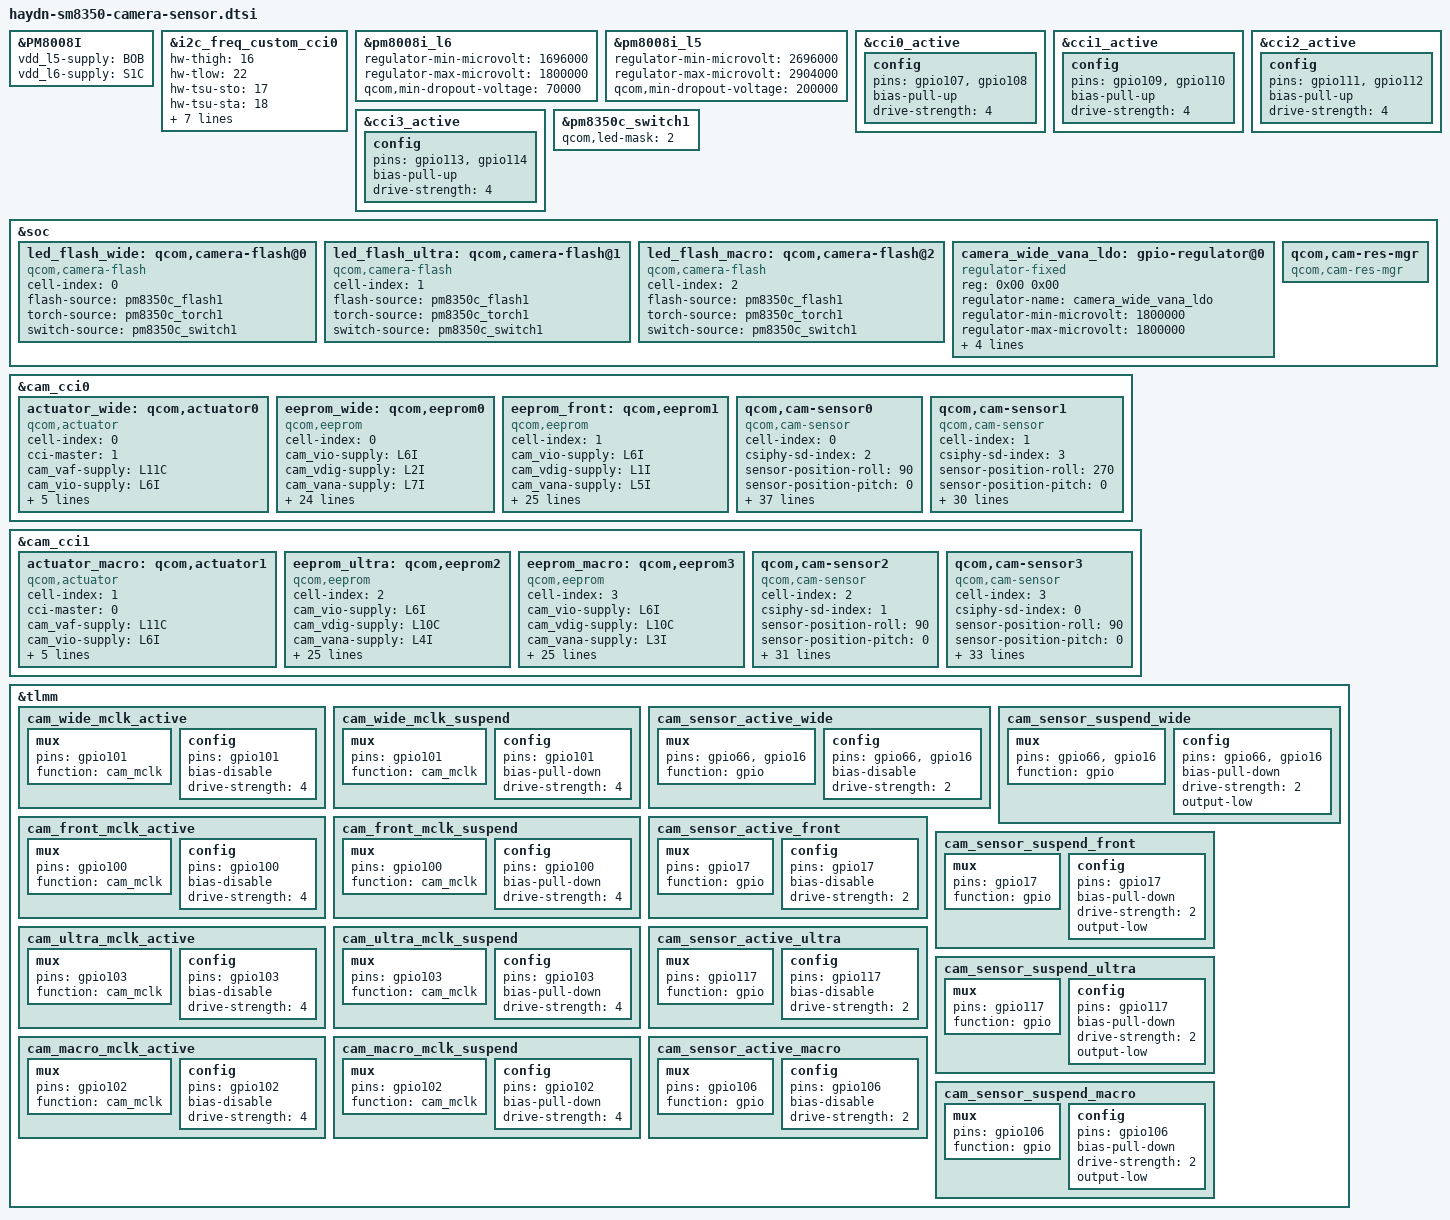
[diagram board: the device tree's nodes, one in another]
#include <dt-bindings/clock/qcom,camcc-lahaina.h>

&PM8008I {
        vdd_l5-supply = <&BOB>;
        vdd_l6-supply = <&S1C>;
};

&i2c_freq_custom_cci0 {
	hw-thigh = <16>;
	hw-tlow = <22>;
	hw-tsu-sto = <17>;
	hw-tsu-sta = <18>;
	hw-thd-dat = <16>;
	hw-thd-sta = <15>;
	hw-tbuf = <24>;
	hw-scl-stretch-en = <1>;
	hw-trdhld = <3>;
	hw-tsp = <3>;
	cci-clk-src = <37500000>;
	status = "ok";
};

&pm8008i_l6 {
        regulator-min-microvolt = <1696000>;
        regulator-max-microvolt = <1800000>;
        qcom,min-dropout-voltage = <70000>;
};

&pm8008i_l5 {
        regulator-min-microvolt = <2696000>;
        regulator-max-microvolt = <2904000>;
        qcom,min-dropout-voltage = <200000>;
};

&cci0_active {
	config {
		pins = "gpio107","gpio108";
		bias-pull-up; /* PULL UP*/
		drive-strength = <4>; /* 4 MA */
	};
};

&cci1_active {
	config {
		pins = "gpio109","gpio110";
		bias-pull-up; /* PULL UP*/
		drive-strength = <4>; /* 4 MA */
	};
};

&cci2_active {
	config {
		pins = "gpio111","gpio112";
		bias-pull-up; /* PULL UP*/
		drive-strength = <4>; /* 4 MA */
	};
};

&cci3_active {
	config {
		pins = "gpio113","gpio114";
		bias-pull-up; /* PULL UP*/
		drive-strength = <4>; /* 4 MA */
	};
};

&pm8350c_switch1 {
	qcom,led-mask = <2>; /* Channels 2*/
};

&soc {
	led_flash_wide: qcom,camera-flash@0 {
		cell-index = <0>;
		compatible = "qcom,camera-flash";
		flash-source = <&pm8350c_flash1>;
		torch-source = <&pm8350c_torch1>;
		switch-source = <&pm8350c_switch1>;
		status = "ok";
	};

	led_flash_ultra: qcom,camera-flash@1 {
		cell-index = <1>;
		compatible = "qcom,camera-flash";
		flash-source = <&pm8350c_flash1>;
		torch-source = <&pm8350c_torch1>;
		switch-source = <&pm8350c_switch1>;
		status = "ok";
	};

	led_flash_macro: qcom,camera-flash@2 {
		cell-index = <2>;
		compatible = "qcom,camera-flash";
		flash-source = <&pm8350c_flash1>;
		torch-source = <&pm8350c_torch1>;
		switch-source = <&pm8350c_switch1>;
		status = "ok";
	};

	camera_wide_vana_ldo: gpio-regulator@0 {
		compatible = "regulator-fixed";
		reg = <0x00 0x00>;
		regulator-name = "camera_wide_vana_ldo";
		regulator-min-microvolt = <1800000>;
		regulator-max-microvolt = <1800000>;
		regulator-enable-ramp-delay = <135>;
		enable-active-high;
		gpio = <&tlmm 66 0>;
                vin-supply = <&S1C>;
	};

	qcom,cam-res-mgr {
		compatible = "qcom,cam-res-mgr";
	};
};

&cam_cci0 {
        actuator_wide: qcom,actuator0 {
                cell-index = <0>;
                compatible = "qcom,actuator";
                cci-master = <1>;
                cam_vaf-supply = <&L11C>;
                cam_vio-supply = <&L6I>;
                regulator-names = "cam_vaf", "cam_vio";
                rgltr-cntrl-support;
                rgltr-min-voltage = <2800000 1800000>;
                rgltr-max-voltage = <2800000 1800000>;
                rgltr-load-current = <300000 10000>;
                status = "ok";
        };

	eeprom_wide: qcom,eeprom0 {
		cell-index = <0>;
		compatible = "qcom,eeprom";
		cam_vio-supply = <&L6I>;
		cam_vdig-supply = <&L2I>;
		cam_vana-supply = <&L7I>;
		cam_v_custom1-supply = <&camera_wide_vana_ldo>;
		cam_clk-supply = <&cam_cc_titan_top_gdsc>;
		cam_bob-supply = <&pm8350c_bob>;
		regulator-names = "cam_vio", "cam_vdig", "cam_vana", "cam_v_custom1",
			"cam_clk", "cam_bob";
		rgltr-cntrl-support;
		rgltr-min-voltage = <1800000 1104000 2904000 1800000 0 3200000>;
		rgltr-max-voltage = <1800000 1104000 2904000 1800000 0 3960000>;
		rgltr-load-current = <4800 120000 970000 87000 0 2000000>;
		gpio-no-mux = <0>;
		pinctrl-names = "cam_default", "cam_suspend";
		pinctrl-0 = <&cam_sensor_active_wide>;
		pinctrl-1 = <&cam_sensor_suspend_wide>;
		gpios = <&tlmm 101 0>,
			<&tlmm 16 0>;
		gpio-reset = <1>;
		gpio-req-tbl-num = <0 1>;
		gpio-req-tbl-flags = <1 0>;
		gpio-req-tbl-label = "CAMIF_MCLK1",
					"CAM_RESET1";
		cci-master = <1>;
		clocks = <&clock_camcc CAM_CC_MCLK1_CLK>;
		clock-names = "cam_clk";
		clock-cntl-level = "nominal";
		clock-rates = <19200000>;
		status = "ok";
	};

	eeprom_front: qcom,eeprom1 {
		cell-index = <1>;
		compatible = "qcom,eeprom";
		cam_vio-supply = <&L6I>;
		cam_vdig-supply = <&L1I>;
		cam_vana-supply = <&L5I>;
		cam_clk-supply = <&cam_cc_titan_top_gdsc>;
		cam_bob-supply = <&pm8350c_bob>;
		regulator-names = "cam_vio", "cam_vdig", "cam_vana",
			"cam_clk", "cam_bob";
		rgltr-cntrl-support;
		rgltr-min-voltage = <1800000 1056000 2800000 0 3200000>;
		rgltr-max-voltage = <1800000 1056000 2800000 0 3960000>;
		rgltr-load-current = <10000 140000 280000 0 2000000>;
		gpio-no-mux = <0>;
		pinctrl-names = "cam_default", "cam_suspend";
		pinctrl-0 = <&cam_sensor_active_front
			&cam_front_mclk_active>;
		pinctrl-1 = <&cam_sensor_suspend_front
			&cam_front_mclk_suspend>;
		gpios = <&tlmm 100 0>,
			<&tlmm 17 0>;
		gpio-reset = <1>;
		gpio-req-tbl-num = <0 1>;
		gpio-req-tbl-flags = <1 0>;
		gpio-req-tbl-label = "CAMIF_MCLK0",
					"CAM_RESET0";
		cci-master = <0>;
		clocks = <&clock_camcc CAM_CC_MCLK0_CLK>;
		clock-names = "cam_clk";
		clock-cntl-level = "nominal";
		clock-rates = <19200000>;
		status = "ok";
	};

	// wide IMX686 64M AVDD 2.8V
	// wide S5KHM2 108M AVDD 2.9V
	qcom,cam-sensor0 {
		cell-index = <0>;
		compatible = "qcom,cam-sensor";
		csiphy-sd-index = <2>;
		sensor-position-roll = <90>;
		sensor-position-pitch = <0>;
		sensor-position-yaw = <180>;
		eeprom-src = <&eeprom_wide>;
		actuator-src = <&actuator_wide>;
		led-flash-src = <&led_flash_wide>;
		cam_vio-supply = <&L6I>;
		cam_vaf_supply = <&L11C>;
		cam_vdig-supply = <&L2I>;
		cam_vana-supply = <&L7I>;
                cam_vana1-supply = <&L2I>;
		cam_v_custom1-supply = <&camera_wide_vana_ldo>;
		cam_v_custom2-supply = <&L7I>;//Hm2 AVDD
		cam_clk-supply = <&cam_cc_titan_top_gdsc>;
		cam_bob-supply = <&pm8350c_bob>;
		regulator-names = "cam_vio", "cam_vdig", "cam_vana", "cam_vaf", "cam_vana1", "cam_v_custom1", "cam_v_custom2",
			"cam_clk", "cam_bob";
		rgltr-cntrl-support;
		rgltr-min-voltage = <1800000 1104000 2904000 2800000 1056000 1800000 2800000 0 3200000>;
		rgltr-max-voltage = <1800000 1104000 2904000 2800000 1056000 1800000 2800000 0 3960000>;
		rgltr-load-current = <4800 120000 970000 106000 87000 2000000 2000000 0 2000000>;
		gpio-no-mux = <0>;
                pinctrl-names = "cam_default", "cam_suspend";
                pinctrl-0 = <&cam_sensor_active_wide
                        &cam_wide_mclk_active>;
                pinctrl-1 = <&cam_sensor_suspend_wide
                        &cam_wide_mclk_suspend>;
		gpios = <&tlmm 101 0>,
			<&tlmm 16 0>;
		gpio-reset = <1>;
		gpio-req-tbl-num = <0 1>;
		gpio-req-tbl-flags = <1 0>;
		gpio-req-tbl-label = "CAMIF_MCLK1",
					"CAM_RESET1";
		cci-master = <1>;
		clocks = <&clock_camcc CAM_CC_MCLK1_CLK>;
		clock-names = "cam_clk";
		clock-cntl-level = "nominal";
		clock-rates = <19200000>;
		status = "ok";
	};

	// Front 20M
	qcom,cam-sensor1 {
		cell-index = <1>;
		compatible = "qcom,cam-sensor";
		csiphy-sd-index = <3>;
		sensor-position-roll = <270>;
		sensor-position-pitch = <0>;
		sensor-position-yaw = <0>;
		eeprom-src = <&eeprom_front>;
		cam_vio-supply = <&L6I>;
		cam_vdig-supply = <&L1I>;
		cam_vana-supply = <&L5I>;
		cam_clk-supply = <&cam_cc_titan_top_gdsc>;
		cam_bob-supply = <&pm8350c_bob>;
		regulator-names = "cam_vio", "cam_vdig", "cam_vana",
			"cam_clk", "cam_bob";
		rgltr-cntrl-support;
		rgltr-min-voltage = <1800000 1056000 2800000 0 3200000>;
		rgltr-max-voltage = <1800000 1056000 2800000 0 3960000>;
		rgltr-load-current = <10000 140000 280000 0 2000000>;
		gpio-no-mux = <0>;
		pinctrl-names = "cam_default", "cam_suspend";
		pinctrl-0 = <&cam_sensor_active_front
			&cam_front_mclk_active>;
		pinctrl-1 = <&cam_sensor_suspend_front
			&cam_front_mclk_suspend>;
		gpios = <&tlmm 100 0>,
			<&tlmm 17 0>;
		gpio-reset = <1>;
		gpio-req-tbl-num = <0 1>;
		gpio-req-tbl-flags = <1 0>;
		gpio-req-tbl-label = "CAMIF_MCLK0",
					"CAM_RESET0";
		cci-master = <0>;
		clocks = <&clock_camcc CAM_CC_MCLK0_CLK>;
		clock-names = "cam_clk";
		clock-cntl-level = "nominal";
		clock-rates = <19200000>;
		status = "ok";
	};

};

&cam_cci1 {
        actuator_macro: qcom,actuator1 {
                cell-index = <1>;
                compatible = "qcom,actuator";
                cci-master = <0>;
                cam_vaf-supply = <&L11C>;
                cam_vio-supply = <&L6I>;
                regulator-names = "cam_vaf", "cam_vio";
                rgltr-cntrl-support;
                rgltr-min-voltage = <2800000 1800000>;
                rgltr-max-voltage = <2800000 1800000>;
                rgltr-load-current = <300000 10000>;
                status = "ok";
        };

	eeprom_ultra: qcom,eeprom2 {
		cell-index = <2>;
		compatible = "qcom,eeprom";
		cam_vio-supply = <&L6I>;
		cam_vdig-supply = <&L10C>;
		cam_vana-supply = <&L4I>;
		cam_clk-supply = <&cam_cc_titan_top_gdsc>;
		cam_bob-supply = <&pm8350c_bob>;
		regulator-names = "cam_vio", "cam_vdig", "cam_vana"
			,"cam_clk", "cam_bob";
		rgltr-cntrl-support;
		rgltr-min-voltage = <1800000 1200000 2704000 0 3200000>;
		rgltr-max-voltage = <1800000 1200000 2704000 0 3960000>;
		rgltr-load-current = <10000 140000 180000 0 2000000>;
		gpio-no-mux = <0>;
		pinctrl-names = "cam_default", "cam_suspend";
		pinctrl-0 = <&cam_sensor_active_ultra
				&cam_ultra_mclk_active>;
		pinctrl-1 = <&cam_sensor_suspend_ultra
				&cam_ultra_mclk_suspend>;
		gpios = <&tlmm 103 0>,
			<&tlmm 117 0>;
		gpio-reset = <1>;
		gpio-req-tbl-num = <0 1>;
		gpio-req-tbl-flags = <1 0>;
		gpio-req-tbl-label = "CAMIF_MCLK3",
					"CAM_RESET3";
		cci-master = <1>;
		clocks = <&clock_camcc CAM_CC_MCLK3_CLK>;
		clock-names = "cam_clk";
		clock-cntl-level = "nominal";
		clock-rates = <19200000>;
		status = "ok";
	};

	eeprom_macro: qcom,eeprom3 {
		cell-index = <3>;
		compatible = "qcom,eeprom";
		cam_vio-supply = <&L6I>;
		cam_vdig-supply = <&L10C>;
		cam_vana-supply = <&L3I>;
		cam_clk-supply = <&cam_cc_titan_top_gdsc>;
		cam_bob-supply = <&pm8350c_bob>;
		regulator-names = "cam_vio", "cam_vdig", "cam_vana"
			          , "cam_clk", "cam_bob";
		rgltr-cntrl-support;
		rgltr-min-voltage = <1800000 1200000 2800000 0 3200000>;
		rgltr-max-voltage = <1800000 1200000 2800000 0 3960000>;
		rgltr-load-current = <10000 140000 180000 0 2000000>;
		gpio-no-mux = <0>;
		pinctrl-names = "cam_default", "cam_suspend";
		pinctrl-0 = <&cam_sensor_active_macro
				&cam_macro_mclk_active>;
		pinctrl-1 = <&cam_sensor_suspend_macro
				&cam_macro_mclk_suspend>;
		gpios = <&tlmm 102 0>,
			<&tlmm 106 0>;
		gpio-reset = <1>;
		gpio-req-tbl-num = <0 1>;
		gpio-req-tbl-flags = <1 0>;
		gpio-req-tbl-label = "CAMIF_MCLK2",
					"CAM_RESET2";
		cci-master = <0>;
		clocks = <&clock_camcc CAM_CC_MCLK2_CLK>;
		clock-names = "cam_clk";
		clock-cntl-level = "nominal";
		clock-rates = <19200000>;
		status = "ok";
	};

	// Ultra 8M
	qcom,cam-sensor2 {
		cell-index = <2>;
		compatible = "qcom,cam-sensor";
		csiphy-sd-index = <1>;
		sensor-position-roll = <90>;
		sensor-position-pitch = <0>;
		sensor-position-yaw = <180>;
		eeprom-src = <&eeprom_ultra>;
		//actuator-src = <&actuator_ultra>;
		led-flash-src = <&led_flash_ultra>;
		cam_vio-supply = <&L6I>;
		cam_vdig-supply = <&L10C>;
		cam_vana-supply = <&L4I>;
		cam_clk-supply = <&cam_cc_titan_top_gdsc>;
		cam_bob-supply = <&pm8350c_bob>;
		regulator-names = "cam_vio", "cam_vdig", "cam_vana"
			,"cam_clk", "cam_bob";
		rgltr-cntrl-support;
		rgltr-min-voltage = <1800000 1200000 2704000 0 3200000>;
		rgltr-max-voltage = <1800000 1200000 2704000 0 3960000>;
		rgltr-load-current = <10000 140000 180000 0 2000000>;
		gpio-no-mux = <0>;
		pinctrl-names = "cam_default", "cam_suspend";
		pinctrl-0 = <&cam_sensor_active_ultra
				&cam_ultra_mclk_active>;
		pinctrl-1 = <&cam_sensor_suspend_ultra
				&cam_ultra_mclk_suspend>;
		gpios = <&tlmm 103 0>,
			<&tlmm 117 0>;
		gpio-reset = <1>;
		gpio-req-tbl-num = <0 1>;
		gpio-req-tbl-flags = <1 0>;
		gpio-req-tbl-label = "CAMIF_MCLK3",
					"CAM_RESET3";
		cci-master = <1>;
		clocks = <&clock_camcc CAM_CC_MCLK3_CLK>;
		clock-names = "cam_clk";
		clock-cntl-level = "nominal";
		clock-rates = <19200000>;
		status = "ok";
	};

	// Folded 5M MACRO
	qcom,cam-sensor3 {
		cell-index = <3>;
		compatible = "qcom,cam-sensor";
		csiphy-sd-index = <0>;
		sensor-position-roll = <90>;
		sensor-position-pitch = <0>;
		sensor-position-yaw = <180>;
		eeprom-src = <&eeprom_macro>;
		led-flash-src = <&led_flash_macro>;
		actuator-src = <&actuator_macro>;
		cam_vio-supply = <&L6I>;
		cam_vdig-supply = <&L10C>;
		cam_vana-supply = <&L3I>;
		cam_vaf-supply = <&L11C>;
		cam_clk-supply = <&cam_cc_titan_top_gdsc>;
		cam_bob-supply = <&pm8350c_bob>;
		regulator-names = "cam_vio", "cam_vdig", "cam_vana", "cam_vaf"
			          , "cam_clk", "cam_bob";
		rgltr-cntrl-support;
		rgltr-min-voltage = <1800000 1200000 2800000 2800000 0 3200000>;
		rgltr-max-voltage = <1800000 1200000 2800000 2800000 0 3960000>;
		rgltr-load-current = <10000 140000 180000 296000 0 2000000>;
		gpio-no-mux = <0>;
		pinctrl-names = "cam_default", "cam_suspend";
		pinctrl-0 = <&cam_sensor_active_macro
				&cam_macro_mclk_active>;
		pinctrl-1 = <&cam_sensor_suspend_macro
				&cam_macro_mclk_suspend>;
		gpios = <&tlmm 102 0>,
			<&tlmm 106 0>;
		gpio-reset = <1>;
		gpio-req-tbl-num = <0 1>;
		gpio-req-tbl-flags = <1 0>;
		gpio-req-tbl-label = "CAMIF_MCLK2",
					"CAM_RESET2";
		cci-master = <0>;
		clocks = <&clock_camcc CAM_CC_MCLK2_CLK>;
		clock-names = "cam_clk";
		clock-cntl-level = "nominal";
		clock-rates = <19200000>;
		status = "ok";
	};
};

&tlmm {
	cam_wide_mclk_active: cam_wide_mclk_active {
                mux {
                        pins = "gpio101";
                        function = "cam_mclk";
                    };

                config {
                        pins = "gpio101";
                        bias-disable; /* No PULL */
                        drive-strength = <4>; /* 4 MA */
                };
	};

	cam_wide_mclk_suspend: cam_wide_mclk_suspend {
                mux {
                        pins = "gpio101";
                        function = "cam_mclk";
                };

                config {
                        pins = "gpio101";
                        bias-pull-down; /* PULL DOWN */
                        drive-strength = <4>; /* 4 MA */
                };
	};

	cam_sensor_active_wide: cam_sensor_active_wide {
		mux {
			pins = "gpio66", "gpio16";
			function = "gpio";
		};

		config {
			pins = "gpio66", "gpio16";
			bias-disable; /* No PULL */
			drive-strength = <2>; /* 2 MA */
		};
	};

	cam_sensor_suspend_wide: cam_sensor_suspend_wide {
		mux {
			pins = "gpio66", "gpio16";
			function = "gpio";
		};

		config {
			pins = "gpio66", "gpio16";
			bias-pull-down; /* PULL DOWN */
			drive-strength = <2>; /* 2 MA */
			output-low;
		};
	};

	cam_front_mclk_active: cam_front_mclk_active {
		mux {
			pins = "gpio100";
			function = "cam_mclk";
		};

		config {
			pins = "gpio100";
			bias-disable; /* No PULL */
			drive-strength = <4>; /* 4 MA */
		};
	};

	cam_front_mclk_suspend: cam_front_mclk_suspend {
		mux {
			pins = "gpio100";
			function = "cam_mclk";
		};

		config {
			pins = "gpio100";
			bias-pull-down; /* PULL DOWN */
			drive-strength = <4>; /* 4 MA */
		};
	};

	cam_sensor_active_front: cam_sensor_active_front {
		/*AVDD RESET */
		mux {
			pins = "gpio17";
			function = "gpio";
		};

		config {
			pins = "gpio17";
			bias-disable; /* No PULL */
			drive-strength = <2>; /* 2 MA */
		};
	};

	cam_sensor_suspend_front: cam_sensor_suspend_front {
		mux {
			pins = "gpio17";
			function = "gpio";
		};

		config {
			pins = "gpio17";
			bias-pull-down; /* PULL DOWN */
			drive-strength = <2>; /* 2 MA */
			output-low;
		};
	};

	cam_ultra_mclk_active: cam_ultra_mclk_active {
		mux {
			pins = "gpio103";
			function = "cam_mclk";
		};

		config {
			pins = "gpio103";
			bias-disable; /* No PULL */
			drive-strength = <4>; /* 4 MA */
		};
	};

	cam_ultra_mclk_suspend: cam_ultra_mclk_suspend {
		mux {
			pins = "gpio103";
			function = "cam_mclk";
		};

		config {
			pins = "gpio103";
			bias-pull-down; /* PULL DOWN */
			drive-strength = <4>; /* 4 MA */
		};
	};

	cam_sensor_active_ultra: cam_sensor_active_ultra {
		/*AVDD RESET */
		mux {
			pins = "gpio117";
			function = "gpio";
		};

		config {
			pins = "gpio117";
			bias-disable; /* No PULL */
			drive-strength = <2>; /* 2 MA */
		};
	};

	cam_sensor_suspend_ultra: cam_sensor_suspend_ultra {
		mux {
			pins = "gpio117";
			function = "gpio";
		};

		config {
			pins = "gpio117";
			bias-pull-down; /* PULL DOWN */
			drive-strength = <2>; /* 2 MA */
			output-low;
		};
	};

	cam_macro_mclk_active: cam_macro_mclk_active {
		mux {
			pins = "gpio102";
			function = "cam_mclk";
		};

		config {
			pins = "gpio102";
			bias-disable; /* No PULL */
			drive-strength = <4>; /* 2 MA */
		};
	};

	cam_macro_mclk_suspend: cam_macro_mclk_suspend {
		mux {
			pins = "gpio102";
			function = "cam_mclk";
		};

		config {
			pins = "gpio102";
			bias-pull-down; /* PULL DOWN */
			drive-strength = <4>; /* 2 MA */
		};
	};

	cam_sensor_active_macro: cam_sensor_active_macro {
		/*AVDD RESET */
		mux {
			pins = "gpio106";
			function = "gpio";
		};

		config {
			pins = "gpio106";
			bias-disable; /* No PULL */
			drive-strength = <2>; /* 2 MA */
		};
	};

	cam_sensor_suspend_macro: cam_sensor_suspend_macro {
		mux {
			pins = "gpio106";
			function = "gpio";
		};

		config {
			pins = "gpio106";
			bias-pull-down; /* PULL DOWN */
			drive-strength = <2>; /* 2 MA */
			output-low;
		};
	};
};
